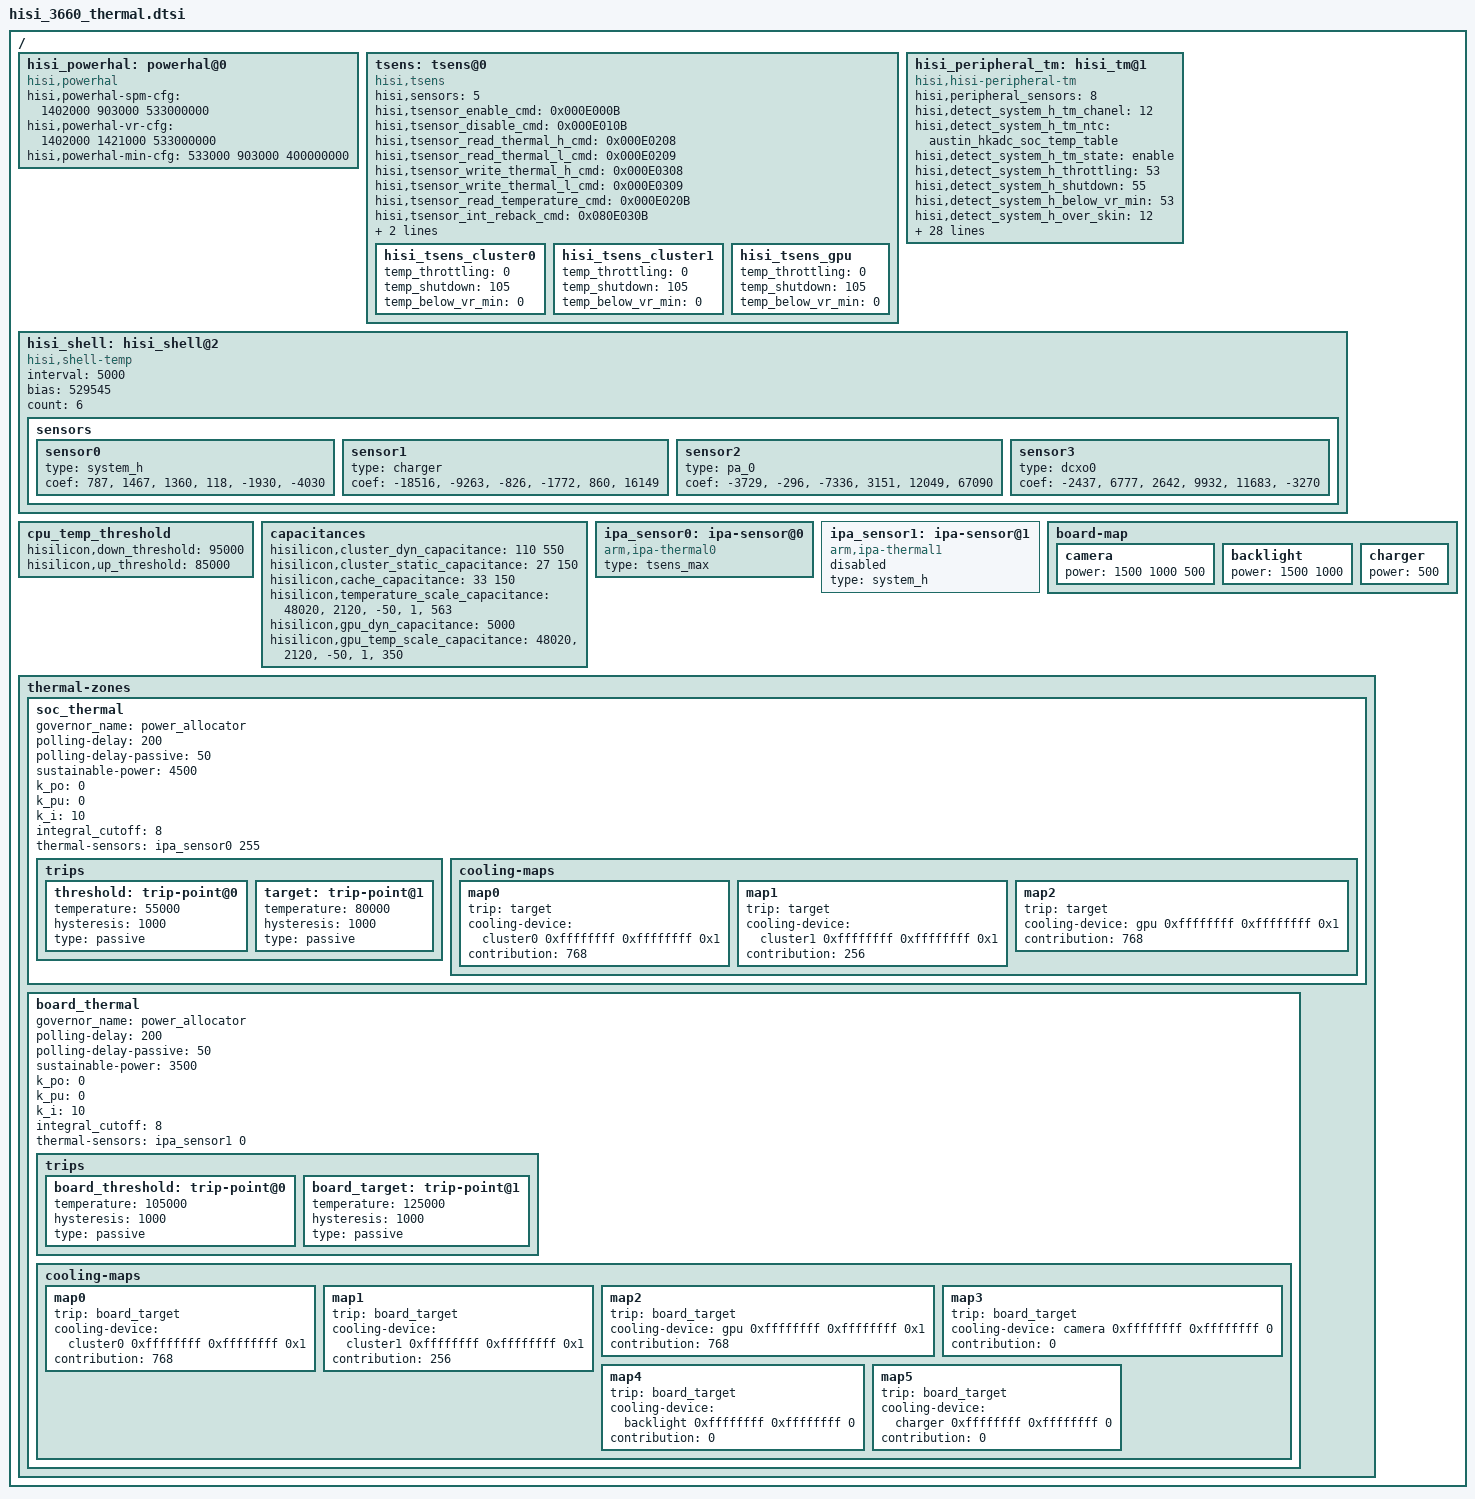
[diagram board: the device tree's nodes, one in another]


  /{
		hisi_powerhal: powerhal@0 {
			compatible = "hisi,powerhal";
			/*CPU_L, CPU_B, GPU*/
			hisi,powerhal-spm-cfg = <1402000 903000 533000000>;
			hisi,powerhal-vr-cfg = <1402000 1421000 533000000>;
			hisi,powerhal-min-cfg = <533000 903000 400000000>;
		};

		tsens: tsens@0{
			compatible = "hisi,tsens";
			hisi,sensors = <5>;
			hisi,tsensor_enable_cmd = <0x000E000B>;
			hisi,tsensor_disable_cmd = <0x000E010B>;
			hisi,tsensor_read_thermal_h_cmd = <0x000E0208>;
			hisi,tsensor_read_thermal_l_cmd = <0x000E0209>;
			hisi,tsensor_write_thermal_h_cmd = <0x000E0308>;
			hisi,tsensor_write_thermal_l_cmd = <0x000E0309>;
			hisi,tsensor_read_temperature_cmd = <0x000E020B>;
			hisi,tsensor_int_reback_cmd = <0x080E030B>;
			hisi,tsensor_adc_start_value = <116>;
			hisi,tsensor_adc_end_value = <922>;
			hisi_tsens_cluster0 {
				temp_throttling = <0>;
				temp_shutdown = <105>;
				temp_below_vr_min = <0>;
			};

			hisi_tsens_cluster1 {
				temp_throttling = <0>;
				temp_shutdown = <105>;
				temp_below_vr_min = <0>;
			};

			hisi_tsens_gpu {
				temp_throttling = <0>;
				temp_shutdown = <105>;
				temp_below_vr_min = <0>;
			};
		};

		hisi_peripheral_tm: hisi_tm@1 {
			compatible = "hisi,hisi-peripheral-tm";
			hisi,peripheral_sensors = <8>;

			hisi,detect_system_h_tm_chanel = <12>;
			hisi,detect_system_h_tm_ntc = "austin_hkadc_soc_temp_table";
			hisi,detect_system_h_tm_state = "enable";
			hisi,detect_system_h_throttling = <53>;
			hisi,detect_system_h_shutdown = <55>;
			hisi,detect_system_h_below_vr_min = <53>;
			hisi,detect_system_h_over_skin = <12>;

			hisi,detect_flash_led_tm_chanel = <11>;
			hisi,detect_flash_led_tm_ntc = "austin_hkadc_soc_temp_table";
			hisi,detect_flash_led_tm_state = "enable";

			hisi,detect_charger_tm_chanel = <5>;
			hisi,detect_charger_tm_ntc = "austin_hkadc_soc_temp_table";
			hisi,detect_charger_tm_state = "enable";

			hisi,detect_pa_0_tm_chanel = <9>;
			hisi,detect_pa_0_tm_ntc = "austin_hkadc_pa_temp_table";
			hisi,detect_pa_0_tm_state = "enable";

			hisi,detect_pa_1_tm_chanel = <13>;
			hisi,detect_pa_1_tm_ntc = "austin_hkadc_pa_temp_table";
			hisi,detect_pa_1_tm_state = "enable";

			hisi,detect_dcxo0_tm_chanel = <3>;
			hisi,detect_dcxo0_tm_ntc = "austin_hkadc_adc_temp_table";
			hisi,detect_dcxo0_tm_state = "enable";

			hisi,detect_shell_tm_chanel = <7>;
			hisi,detect_shell_tm_ntc = "austin_hkadc_soc_temp_table";
			hisi,detect_shell_tm_state = "disable";

			hisi,detect_charger1_tm_chanel = <4>;
			hisi,detect_charger1_tm_ntc = "austin_hkadc_soc_temp_table";
			hisi,detect_charger1_tm_state = "disable";
		};

		hisi_shell: hisi_shell@2 {
			compatible = "hisi,shell-temp";
			interval = <5000>;
			bias = <529545>;
			count = <6>;
			status = "ok";
			sensors {
				sensor0 {
					type = "system_h";
					coef = "787","1467","1360","118","-1930","-4030";
				};
				sensor1 {
					type = "charger";
					coef = "-18516","-9263","-826","-1772","860","16149";
				};
				sensor2 {
					type = "pa_0";
					coef = "-3729","-296","-7336","3151","12049","67090";
				};
				sensor3 {
					type = "dcxo0";
					coef = "-2437","6777","2642","9932","11683","-3270";
				};
			};
		};

		cpu_temp_threshold {
			hisilicon,down_threshold =  <95000>;
			hisilicon,up_threshold = <85000>;
		};

		capacitances {
			hisilicon,cluster_dyn_capacitance  = <110 550>;/*little big*/
			hisilicon,cluster_static_capacitance = <27 150>;/*little big*/
			hisilicon,cache_capacitance  = <33 150>;/*little big*/
			hisilicon,temperature_scale_capacitance = "48020","2120","-50","1","563"; /*temperature_scale_capacitance*/
			hisilicon,gpu_dyn_capacitance  = <5000>;
			hisilicon,gpu_temp_scale_capacitance = "48020","2120","-50","1","350";
		};

		ipa_sensor0: ipa-sensor@0 {
			type = "tsens_max";
			compatible = "arm,ipa-thermal0";
			#thermal-sensor-cells = <1>;
			status = "ok";
		};

		ipa_sensor1: ipa-sensor@1 {
			type = "system_h";
			compatible = "arm,ipa-thermal1";
			#thermal-sensor-cells = <1>;
			status = "disabled";
		};

		board-map {
			camera: camera {
				power = <1500 1000 500>;
				#cooling-cells = <3>;
			};
			backlight: backlight {
				power = <1500 1000>;
				#cooling-cells = <3>;
			};
			charger: charger {
				power = <500>;
				#cooling-cells = <3>;
			};
		};

		thermal-zones {
			soc_thermal {
				governor_name = "power_allocator";
				polling-delay = <200>;
				polling-delay-passive = <50>;
				sustainable-power = <4500>;
				k_po = <0>;
				k_pu = <0>;
				k_i = <10>;
				integral_cutoff = <8>;
				thermal-sensors = <&ipa_sensor0 255>;

				trips {
				         threshold: trip-point@0 {
				                    temperature = <55000>;
				                    hysteresis = <1000>;
				                    type = "passive";
				        };
				        target: trip-point@1 {
				                   temperature = <80000>;
				                   hysteresis = <1000>;
				                   type = "passive";
				        };
				};

				cooling-maps {
				           map0 {
				                   trip = <&target>;
				                   cooling-device = <&cluster0 0xffffffff 0xffffffff 0x1>;
				                   contribution = <768>;
				           };
				           map1 {
				                   trip = <&target>;
				                   cooling-device = <&cluster1 0xffffffff 0xffffffff 0x1>;
				                   contribution = <256>;
				           };
				           map2 {
				                   trip = <&target>;
				                   cooling-device = <&gpu 0xffffffff 0xffffffff 0x1>;
				                   contribution = <768>;
				           };
				};

			};

			board_thermal {
				governor_name = "power_allocator";
				polling-delay = <200>;
				polling-delay-passive = <50>;
				sustainable-power = <3500>;
				k_po = <0>;
				k_pu = <0>;
				k_i = <10>;
				integral_cutoff = <8>;
				thermal-sensors = <&ipa_sensor1 0>;

				trips {
				         board_threshold: trip-point@0 {
				                    temperature = <105000>;
				                    hysteresis = <1000>;
				                    type = "passive";
				        };
				        board_target: trip-point@1 {
				                   temperature = <125000>;
				                   hysteresis = <1000>;
				                   type = "passive";
				        };
				};

				cooling-maps {
				           map0 {
				                   trip = <&board_target>;
				                   cooling-device = <&cluster0 0xffffffff 0xffffffff 0x1>;
				                   contribution = <768>;
				           };
				           map1 {
				                   trip = <&board_target>;
				                   cooling-device = <&cluster1 0xffffffff 0xffffffff 0x1>;
				                   contribution = <256>;
				           };
				           map2 {
				                   trip = <&board_target>;
				                   cooling-device = <&gpu 0xffffffff 0xffffffff 0x1>;
				                   contribution = <768>;
				           };
				           map3 {
				                   trip = <&board_target>;
				                   cooling-device = <&camera 0xffffffff 0xffffffff 0>;
				                   contribution = <0>;
				           };
				           map4 {
				                   trip = <&board_target>;
				                   cooling-device = <&backlight 0xffffffff 0xffffffff 0>;
				                   contribution = <0>;
				           };
				           map5 {
				                   trip = <&board_target>;
				                   cooling-device = <&charger 0xffffffff 0xffffffff 0>;
				                   contribution = <0>;
				           };
				};

			};

		};

	};
